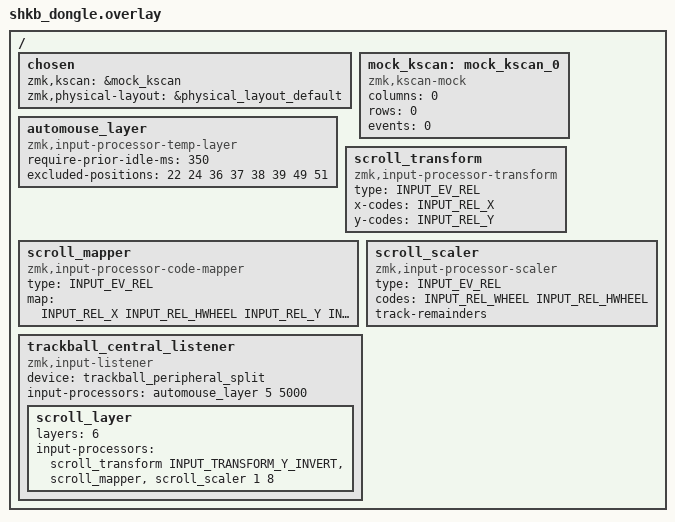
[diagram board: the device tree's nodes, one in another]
#include "shkb.dtsi"
#include <dt-bindings/input/input-event-codes.h>
#include <dt-bindings/zmk/input_transform.h>

/*
 * Dongle (XIAO BLE or Prospector) – Central role, USB-connected to host.
 * Receives key events from both peripherals via BLE.
 * Receives trackball events from right peripheral via input-split relay,
 * then applies AutoMouse-layer and Scroll-layer processing here.
 */
/ {
    chosen {
        zmk,kscan = &mock_kscan;
        zmk,physical-layout = &physical_layout_default;
    };

    /* No physical keys on the dongle – use a mock kscan */
    mock_kscan: mock_kscan_0 {
        compatible = "zmk,kscan-mock";
        columns = <0>;
        rows = <0>;
        events = <0>;
    };

    /* ── Input processors (identical to normal-mode left-central) ─────── */

    automouse_layer: automouse_layer {
        compatible = "zmk,input-processor-temp-layer";
        #input-processor-cells = <2>;
        require-prior-idle-ms = <350>; /* キー押下後、何msオートマウスレイヤに入らないようにするか、誤爆防止 */
        excluded-positions = <22 24 36 37 38 39 49 51>;
    };

    scroll_transform: scroll_transform {
        compatible = "zmk,input-processor-transform";
        #input-processor-cells = <1>;
        type = <INPUT_EV_REL>;
        x-codes = <INPUT_REL_X>;
        y-codes = <INPUT_REL_Y>;
    };

    scroll_mapper: scroll_mapper {
        compatible = "zmk,input-processor-code-mapper";
        #input-processor-cells = <0>;
        type = <INPUT_EV_REL>;
        map = <INPUT_REL_X INPUT_REL_HWHEEL
               INPUT_REL_Y INPUT_REL_WHEEL>;
    };

    scroll_scaler: scroll_scaler {
        compatible = "zmk,input-processor-scaler";
        #input-processor-cells = <2>;
        type = <INPUT_EV_REL>;
        codes = <INPUT_REL_WHEEL INPUT_REL_HWHEEL>;
        track-remainders;
    };

    /* ── Trackball listener: receives from right peripheral via BLE ──── */
    trackball_central_listener: trackball_central_listener {
        compatible = "zmk,input-listener";
        device = <&trackball_peripheral_split>;
        /* Layer 5 = Mouse (auto-activate on trackball movement) */
        input-processors = <&automouse_layer 5 5000>;

        scroll_layer {
            /* Layer 6 = Scroll (remap XY → wheel events) */
            layers = <6>;
            input-processors = <&scroll_transform INPUT_TRANSFORM_Y_INVERT
                                 &scroll_mapper
                                 &scroll_scaler 1 8>;
        };
    };
};
